# AC7842x register map
Vendor: AutoChips; Series: AC78; File version: 1.0
CPU: CM4 r0p1, little endian, MPU, FPU, VTOR, 4 interrupt priority bits
Registers are 32-bit, read-write, reset 0x0 unless marked. A register's access mark holds for its fields unless they carry their own. Offsets are from the block's base; [hi:lo] are bit positions.

## CAN0 — Controller Area Network
Base 0x40007000
Same registers: CAN1 0x40007200, CAN2 0x40007400, CAN3 0x40007600, CAN4 0x40007800, CAN5 0x40007A00
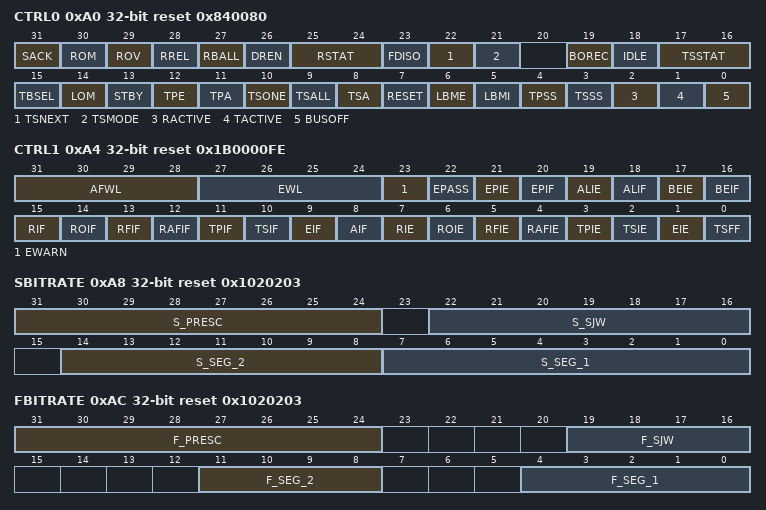
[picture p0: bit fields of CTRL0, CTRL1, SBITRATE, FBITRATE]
0xA0 CTRL0 reset 0x840080 — Config state and transmit/receive control register 0
  [31] SACK — Self-acknowledge when LBME = 1
    0=No self-ack; 1=Self-ack when LBME=1
  [30] ROM — Receive buffer overflow mode
    0=The oldest message will be overwritten; 1=The new message will not be stored
  [29] ROV ro — Receive buffer overflow
    0=No overflow; 1=Overflow. At least one message is lost
  [28] RREL — Receive buffer release
    0=No release; 1=Release: The host has read the RB
  [27] RBALL — Receive buffer stores all data frames
    0=Normal operation; 1=RB stores correct data frames as well as data frames with error
  [26] DREN — DMA receive enable
    0=Disabled; 1=Enabled
  [25:24] RSTAT ro — Receive buffer status bits
    0=Empty; 1=not empty and less than almost full (AFWL); 2=Almost full (programmable threshold by AFWL) but not full and no overflow; 3=Full
  [23] FDISO — FD ISO mode
    0=Bosch CAN FD (non-ISO) mode; 1=ISO CAN FD mode (ISO 11898-1:2015)
  [22] TSNEXT — Transmit buffer secondary next
    0=No action; 1=STB slot filled, select next slot
  [21] TSMODE — Transmit buffer secondary operation mode
    0=FIFO mode; 1=Priority decision mode
  [19] BOREC — Auto busoff recovery
    0=Enable auto busoff recovery; 1=Disable auto busoff recovery
  [18] IDLE ro — CAN bus idle state
    0=No idle state; 1=CAN bus idle state
  [17:16] TSSTAT ro — Transmit secondary status bits
    0=STB is empty; 1=STB is less than or equal to half full; 2=STB is more than half full; 3=STB is full
  [15] TBSEL — Transmit buffer select
    0=PTB (high-priority buffer); 1=STB
  [14] LOM — Listen only mode
    0=Disabled; 1=Enabled
  [13] STBY — Transceiver standby mode
    0=Disabled; 1=Enabled
  [12] TPE — Transmit primary enable
    0=No transmission for the PTB; 1=Transmission enable for the message in the high-priority PTB
  [11] TPA — Transmit primary abort
    0=No abort; 1=Aborts a transmission from PTB which has been requested by TPE=1 but not started yet
  [10] TSONE — Transmit secondary one frame
    0=No transmission for the STB; 1=Transmission enable of one in the STB
  [9] TSALL — Transmit secondary all frames
    0=No transmission for the STB; 1=Transmission enable of all messages in the STB
  [8] TSA — Transmit secondary abort
    0=No abort; 1=Aborts a transmission from STB which has been requested but not started yet
  [7] RESET — reset request bit
    0=No local reset of CAN-CTRL; 1=The host controller performs a local reset of CAN-CTRL
  [6] LBME — Loop back mode, external
    0=Disabled; 1=Enabled
  [5] LBMI — Loop back mode, internal
    0=Disabled; 1=Enabled
  [4] TPSS — Transmission primary single shot mode for PTB
    0=Disabled; 1=Enabled
  [3] TSSS — Transmission secondary single shot mode for STB
    0=Disabled; 1=Enabled
  [2] RACTIVE ro — Reception active
    0=No receive activity; 1=The controller is currently receiving a frame
  [1] TACTIVE ro — Transmission active
    0=No transmit activity; 1=The controller is currently transmitting a frame
  [0] BUSOFF — Bus off status
    0=The controller status is bus on; 1=The controller status is bus off
0xA4 CTRL1 reset 0x1B0000FE — Interrupt enable and flag control register 1
  [31:28] AFWL — Receive buffer almost full warning limit
  [27:24] EWL — Programmable error warnig limit
  [23] EWARN ro — Error warning limit reached
    0=The values in both counters are less than EWL; 1=One of the error counters RECNT or TECNT is equal or bigger than EWL
  [22] EPASS ro — Error passive mode active
    0=Not active (node is error active); 1=Active (node is error active)
  [21] EPIE — Error passive interrupt enable
    0=Disabled; 1=Enabled
  [20] EPIF — Error passive interrupt flag
    0=No error status change; 1=The error status changes from error active to error passive or vice versa
  [19] ALIE — Arbitration lost interrupt enable
    0=Disabled; 1=Enabled
  [18] ALIF — Arbitration lost interrupt flag
    0=No arbitration lost has occurred; 1=Arbitration lost has occurred
  [17] BEIE — Bus error interrupt enable
    0=Disabled; 1=Enabled
  [16] BEIF — Bus error interrupt flag
    0=No bus error has occurred; 1=Bus error has occurred
  [15] RIF — Receive interrupt flag
    0=No frame has been received; 1=Data or a remote frame has been received and is available in the receive buffer
  [14] ROIF — RB overflow interrupt flag
    0=No RB overwritten; 1=At least one received message has been overwritten in the RB
  [13] RFIF — RB full interrupt flag
    0=The RB FIFO is not full; 1=All RBs are full
  [12] RAFIF — RB almost full interrupt flag
    0=Number of filled RB slots less than AFWL; 1=Number of filled RB slots more than or equal AFWL
  [11] TPIF — Transmission primary interrupt flag
    0=No transmission of the PTB has been completed; 1=The requested transmission of the PTB has been successfully completed
  [10] TSIF — Transmission secondary interrupt flag
    0=No transmission of the STB has been completed successfully; 1=The requested transmission of the STB has been successfully completed
  [9] EIF — Error interrupt flag
    0=There has been no change; 1=The border of the error warning limit has been crossed in either direction, or the BUSOFF bit has been changed in either direction
  [8] AIF — Abort interrupt flag
    0=No abort has been executed; 1=After setting TPA or TSA the appropriated message(s) have been aborted
  [7] RIE — Receive interrupt enable
    0=Disabled; 1=Enabled
  [6] ROIE — RB overflow interrupt enable
    0=Disabled; 1=Enabled
  [5] RFIE — RB full interrupt enable
    0=Disabled; 1=Enabled
  [4] RAFIE — RB almost full interrupt enable
    0=Disabled; 1=Enabled
  [3] TPIE — Transmit primary interrupt enable
    0=Disabled; 1=Enabled
  [2] TSIE — Transmit secondary interrupt enable
    0=Disabled; 1=Enabled
  [1] EIE — Error interrupt enable
    0=Disabled; 1=Enabled
  [0] TSFF ro — Transmit secondary buffer full flag
    0=The STB is not filled with the maximal number of messages; 1=The STB is filled with the maximal number of messages
0xA8 SBITRATE reset 0x1020203 — CAN normal bitrate configuration register
  [31:24] S_PRESC — Prescaler
  [22:16] S_SJW — Synchronization jump width
  [14:8] S_SEG_2 — Bit timing segment 2
  [7:0] S_SEG_1 — Bit timing segment 1
0xAC FBITRATE reset 0x1020203 — CAN FD data bitrate configuration register
  [31:24] F_PRESC — Prescaler
  [19:16] F_SJW — Synchronization jump width
  [11:8] F_SEG_2 — Bit timing segment 2
  [4:0] F_SEG_1 — Bit timing segment 1
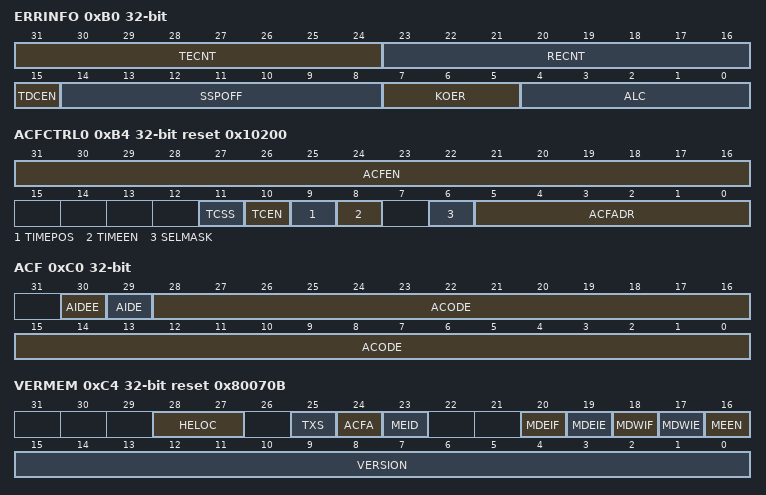
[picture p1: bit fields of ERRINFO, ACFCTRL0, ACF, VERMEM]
0xB0 ERRINFO — Error type and error counter register
  [31:24] TECNT ro — Transmit error count
  [23:16] RECNT ro — Receive error count
  [15] TDCEN — Transmitter delay compensation enable
    0=Disabled; 1=Enabled
  [14:8] SSPOFF — Second sample point offset
  [7:5] KOER ro — Kind of error
    0=No error; 1=Bit error; 2=Form error; 3=Stuff error; 4=Acknowledge error; 5=CRC error; 6=Other error
  [4:0] ALC ro — Arbitration lost capture
0xB4 ACFCTRL0 reset 0x10200 — Acceptance filter control register 0
  [31:16] ACFEN — Acceptance filter enable(0-15)
  [11] TCSS — Time-stamping clock source select
    0=External clock; 1=Bit time clock
  [10] TCEN — Time-stamping counter enable
    0=Disabled; 1=Enabled
  [9] TIMEPOS — Time-stamping position
    0=SOF; 1=EOF
  [8] TIMEEN — Time-stamping enable
    0=Disabled; 1=Enabled
  [6] SELMASK — Select acceptance mask
    0=Registers ACF_x point to acceptance code; 1=Registers ACF_x point to acceptance mask
  [5:0] ACFADR — Acceptance filter address
0xB8 ACFCTRL1 — Acceptance filter control register 1
  [31:0] ACFEN — Acceptance filter enable(16-47)
0xBC ACFCTRL2 — Acceptance filter control register 2
  [11:0] ACFEN — Acceptance filter enable(48-59)
0xC0 ACF — Acceptance code register
  [30] AIDEE — Acceptance mask IDE bit check enable
    0=Acceptance filter accepts both standard or extended frames; 1=Acceptance filter accepts either standard or extended as defined by AIDE
  [29] AIDE — Acceptance mask IDE bit value
    0=Acceptance filter accepts only standard frames; 1=Acceptance filter accepts only extended frames
  [28:0] ACODE — Acceptance code
0xC4 VERMEM reset 0x80070B — Version and memory protection register
  [28:27] HELOC ro — Host side memory error location
    0=No error during access from host side; 1=Error during access from host side in TBUF; 2=Error during access from host side in RBUF; 3=Error during access from host side in ACF
  [25] TXS ro — Transmission stop
    0=Normal operation; 1=Transmission stoped
  [24] ACFA ro — Acceptance filter accept
    0=Normal operation of ACF; 1=ACF disabled: all received frames are accepted
  [23] MEID ro — Memory ECC initialization is done
    0=Memory ECC initialization is not done; 1=Memory ECC initialization is done
  [20] MDEIF — Memory data error interrupt flag
    0=No memory data error is occured; 1=Memory data error is occured
  [19] MDEIE — Memory data error interrupt enable
    0=Disabled; 1=Enabled
  [18] MDWIF — Memory data warning interrupt flag
    0=No memory data warning is occured; 1=Memory data warning is occured
  [17] MDWIE — Memory data warning interrupt enable
    0=Disabled; 1=Enabled
  [16] MEEN — Memory ECC enable
    0=Disabled; 1=Enabled
  [15:0] VERSION ro — Version of CAN-CTRL
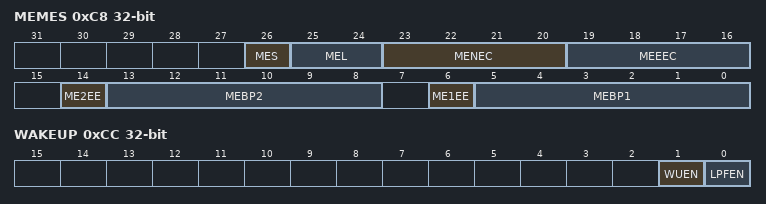
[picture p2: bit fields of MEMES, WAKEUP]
0xC8 MEMES — Memory error simulation register
  [26] MES — Memory error side
    0=Host side; 1=CAN side
  [25:24] MEL — Memory error location
    0=ACF; 1=TBUF; 2=RBUF
  [23:20] MENEC — Memory error: no error counter
  [19:16] MEEEC — Memory error: error enable counter
  [14] ME2EE — Memory error: 2nd error enable
    0=Disabled; 1=Enabled
  [13:8] MEBP2 — Memory error: bit position 2
  [6] ME1EE — Memory error: 1st error enable
    0=Disabled; 1=Enabled
  [5:0] MEBP1 — Memory error: bit position 1
0xCC WAKEUP — Wakeup configuration register
  [1] WUEN — Wakeup enable
    0=Disabled; 1=Enabled
  [0] LPFEN — Low pass filter enable
    0=Disabled; 1=Enabled
0xDC TBU — Tx buffer used register
  [4:0] TBUC — Tx buffer used cnt
0xE0 RBU — Rx buffer used register
  [4:0] RBUC — Rx buffer used cnt
